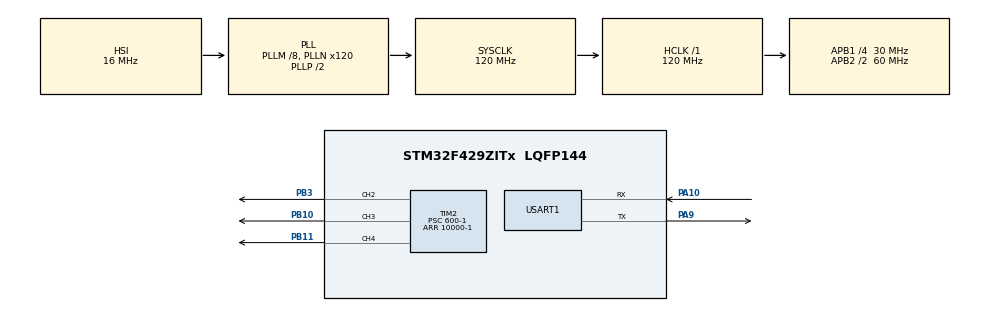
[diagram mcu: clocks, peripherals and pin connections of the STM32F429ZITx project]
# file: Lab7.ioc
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Mcu.Family=STM32F4
Mcu.Name=STM32F429ZITx
Mcu.Package=LQFP144
NVIC.PriorityGroup=NVIC_PRIORITYGROUP_4
PA10.Mode=Asynchronous
PA10.Signal=USART1_RX
PA9.Mode=Asynchronous
PA9.Signal=USART1_TX
PB10.GPIO_Speed=GPIO_SPEED_FREQ_VERY_HIGH
PB10.Signal=S_TIM2_CH3
PB11.GPIO_Speed=GPIO_SPEED_FREQ_VERY_HIGH
PB11.Signal=S_TIM2_CH4
PB3.GPIO_Speed=GPIO_SPEED_FREQ_VERY_HIGH
PB3.Signal=S_TIM2_CH2
ProjectManager.HeapSize=0x200
ProjectManager.StackSize=0x400
ProjectManager.TargetToolchain=STM32CubeIDE
RCC.48MHZClocksFreq_Value=60000000
RCC.AHBFreq_Value=120000000
RCC.APB1CLKDivider=RCC_HCLK_DIV4
RCC.APB1Freq_Value=30000000
RCC.APB1TimFreq_Value=60000000
RCC.APB2CLKDivider=RCC_HCLK_DIV2
RCC.APB2Freq_Value=60000000
RCC.APB2TimFreq_Value=120000000
RCC.CortexFreq_Value=120000000
RCC.HCLKFreq_Value=120000000
RCC.HSE_VALUE=25000000
RCC.HSI_VALUE=16000000
RCC.LSE_VALUE=32768
RCC.PLLM=8
RCC.PLLN=120
RCC.SYSCLKFreq_VALUE=120000000
RCC.SYSCLKSource=RCC_SYSCLKSOURCE_PLLCLK
RCC.VCOOutputFreq_Value=240000000
SH.S_TIM2_CH2.0=TIM2_CH2,PWM Generation2 CH2
SH.S_TIM2_CH3.0=TIM2_CH3,PWM Generation3 CH3
SH.S_TIM2_CH4.0=TIM2_CH4,PWM Generation4 CH4
TIM2.Channel-PWM\ Generation2\ CH2=TIM_CHANNEL_2
TIM2.Channel-PWM\ Generation3\ CH3=TIM_CHANNEL_3
TIM2.Channel-PWM\ Generation4\ CH4=TIM_CHANNEL_4
TIM2.Period=10000-1
TIM2.Prescaler=600-1
USART1.VirtualMode=VM_ASYNC
VP_TIM2_VS_ClockSourceINT.Mode=Internal
board=custom

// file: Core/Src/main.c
/* USER CODE BEGIN Header */
/**
  ******************************************************************************
  * @file           : main.c
  * @brief          : Main program body
  ******************************************************************************
  * @attention
  *
  * <h2><center>&copy; Copyright (c) 2021 STMicroelectronics.
  * All rights reserved.</center></h2>
  *
  * This software component is licensed by ST under BSD 3-Clause license,
  * the "License"; You may not use this file except in compliance with the
  * License. You may obtain a copy of the License at:
  *                        opensource.org/licenses/BSD-3-Clause
  *
  ******************************************************************************
  */
/* USER CODE END Header */
#include "main.h"
#include "tim.h"
#include "usart.h"
#include "gpio.h"

/* USER CODE BEGIN PV */
	uint8_t pwmR;
	uint8_t pwmG;
	uint8_t pwmB;
/* USER CODE END PV */

void SystemClock_Config(void);

int main(void)
{

  /* MCU Configuration--------------------------------------------------------*/

  /* Reset of all peripherals, Initializes the Flash interface and the Systick. */
  HAL_Init();

  /* Configure the system clock */
  SystemClock_Config();

  /* Initialize all configured peripherals */
  MX_GPIO_Init();
  MX_TIM2_Init();
  MX_USART1_UART_Init();
  /* USER CODE BEGIN 2 */
  float dutyCycleR = 0.25;
  float dutyCycleG = 0;
  float dutyCycleB = 0;
  /* USER CODE END 2 */

  /* Infinite loop */
  while (1)
  {

    /* USER CODE BEGIN 3 */
	  htim2.Instance -> CCR2 = (10000-1) * dutyCycleR;
	  HAL_TIM_PWM_Start(&htim2, TIM_CHANNEL_2);
	  HAL_Delay(100);
	  HAL_TIM_PWM_Stop(&htim2, TIM_CHANNEL_2);
	  pwmR = (GPIOB->IDR & GPIO_PIN_3) >>3;

//	  char inp='a';

//	  (HAL_UART_Receive(&huart1, (uint8_t*)&inp, 1,100));
//	  if(inp=='r'||inp=='g'||inp=='b'){
//		  (HAL_UART_Transmit(&huart1, (uint8_t*)&inp, 1,100));
//	  }
//	  HAL_TIM_PWM_Stop(&htim2, TIM_CHANNEL_2);
//	  HAL_TIM_PWM_Stop(&htim2, TIM_CHANNEL_3);
//	  HAL_TIM_PWM_Stop(&htim2, TIM_CHANNEL_4);
//	  if(inp == 'r')
//	  {
//		  if(dutyCycleR<1){
//			  dutyCycleR = dutyCycleR+0.2;}
//		  else{
//			  dutyCycleR = 0;
//		  }
//	  }
//	  if(inp == 'g')
//	  {
//		  if(dutyCycleG<1){
//		  			  dutyCycleG = dutyCycleG+0.2;}
//		  		  else{
//		  			  dutyCycleG = 0;
//		  		  }
//	  }
//	  if(inp == 'b'){
//		  if(dutyCycleB<1){
//		  			  dutyCycleB = dutyCycleB+0.2;}
//		  		  else{
//		  			  dutyCycleB = 0;
//		  		  }
//	  }
//
//	  htim2.Instance -> CCR2 = (10000-1) * dutyCycleR;
//	  htim2.Instance -> CCR3 = (10000-1) * dutyCycleG;
//	  htim2.Instance -> CCR4 = (10000-1) * dutyCycleB;
//	  HAL_TIM_PWM_Start(&htim2, TIM_CHANNEL_2);
//	  HAL_TIM_PWM_Start(&htim2, TIM_CHANNEL_3);
//	  HAL_TIM_PWM_Start(&htim2, TIM_CHANNEL_4);
//	  pwmR = (GPIOB->IDR & GPIO_PIN_3) >>3;
//	  pwmG = (GPIOB->IDR & GPIO_PIN_10) >>10;
//	  pwmB = (GPIOB->IDR & GPIO_PIN_11) >>11;

  }
  /* USER CODE END 3 */
}

void SystemClock_Config(void)
{
  RCC_OscInitTypeDef RCC_OscInitStruct = {0};
  RCC_ClkInitTypeDef RCC_ClkInitStruct = {0};

  /** Configure the main internal regulator output voltage
  */
  __HAL_RCC_PWR_CLK_ENABLE();
  __HAL_PWR_VOLTAGESCALING_CONFIG(PWR_REGULATOR_VOLTAGE_SCALE3);
  /** Initializes the RCC Oscillators according to the specified parameters
  * in the RCC_OscInitTypeDef structure.
  */
  RCC_OscInitStruct.OscillatorType = RCC_OSCILLATORTYPE_HSI;
  RCC_OscInitStruct.HSIState = RCC_HSI_ON;
  RCC_OscInitStruct.HSICalibrationValue = RCC_HSICALIBRATION_DEFAULT;
  RCC_OscInitStruct.PLL.PLLState = RCC_PLL_ON;
  RCC_OscInitStruct.PLL.PLLSource = RCC_PLLSOURCE_HSI;
  RCC_OscInitStruct.PLL.PLLM = 8;
  RCC_OscInitStruct.PLL.PLLN = 120;
  RCC_OscInitStruct.PLL.PLLP = RCC_PLLP_DIV2;
  RCC_OscInitStruct.PLL.PLLQ = 4;
  if (HAL_RCC_OscConfig(&RCC_OscInitStruct) != HAL_OK)
  {
    Error_Handler();
  }
  /** Initializes the CPU, AHB and APB buses clocks
  */
  RCC_ClkInitStruct.ClockType = RCC_CLOCKTYPE_HCLK|RCC_CLOCKTYPE_SYSCLK
                              |RCC_CLOCKTYPE_PCLK1|RCC_CLOCKTYPE_PCLK2;
  RCC_ClkInitStruct.SYSCLKSource = RCC_SYSCLKSOURCE_PLLCLK;
  RCC_ClkInitStruct.AHBCLKDivider = RCC_SYSCLK_DIV1;
  RCC_ClkInitStruct.APB1CLKDivider = RCC_HCLK_DIV4;
  RCC_ClkInitStruct.APB2CLKDivider = RCC_HCLK_DIV2;

  if (HAL_RCC_ClockConfig(&RCC_ClkInitStruct, FLASH_LATENCY_3) != HAL_OK)
  {
    Error_Handler();
  }
}

void Error_Handler(void)
{
  __disable_irq();
  while (1)
  {
  }
}

/************************ (C) COPYRIGHT STMicroelectronics *****END OF FILE****/
